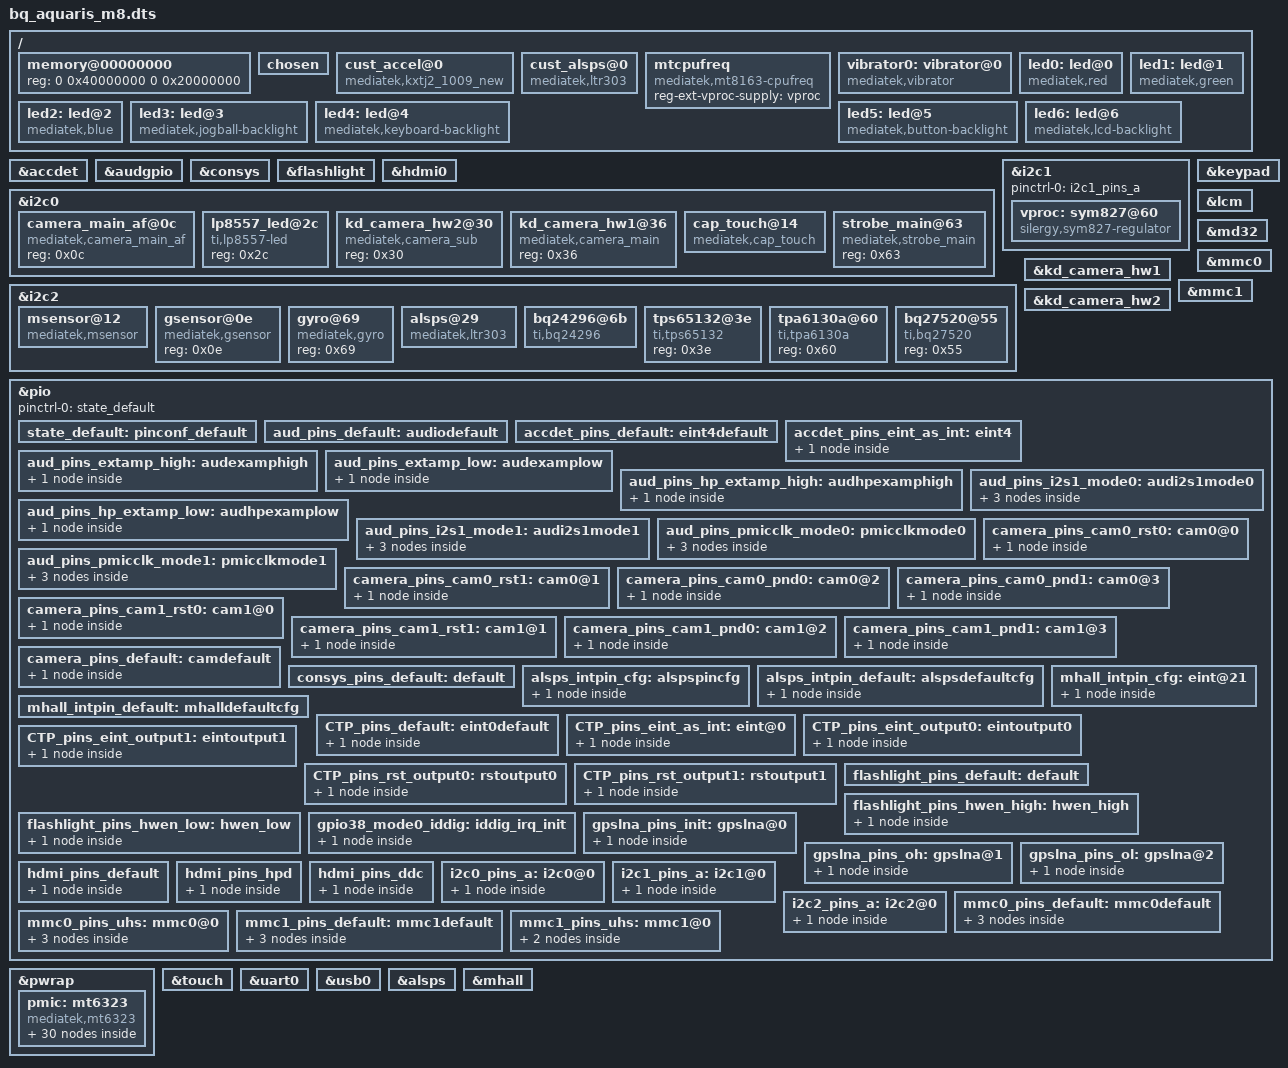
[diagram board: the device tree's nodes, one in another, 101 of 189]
/*
 * Copyright (c) 2014-2015 MediaTek Inc.
 *
 * This program is free software; you can redistribute it and/or modify
 * it under the terms of the GNU General Public License version 2 as
 * published by the Free Software Foundation.
 *
 * This program is distributed in the hope that it will be useful,
 * MERCHANTABILITY or FITNESS FOR A PARTICULAR PURPOSE.  See the
 * GNU General Public License for more details.
 */

/dts-v1/;

#include "mt8163.dtsi"
#include "bq_aquaris_m8_bat_setting.dtsi"

/ {
	memory@00000000 {
		device_type = "memory";
		reg = <0 0x40000000 0 0x20000000>;
	};

	/* chosen */
	chosen {
		bootargs = "console=ttyS0,921600n1 root=/dev/ram initrd=0x44000200,0x200000";
	};

/* sensor standardization */
	cust_accel@0 {
		compatible = "mediatek,kxtj2_1009_new";
		i2c_num	= <2>;
		i2c_addr = <0x0E 0 0 0>;
		direction = <7>;
		power_id = <0xffff>;
		power_vol = <0>;
		firlen = <0>;
		is_batch_supported = <0>;
	};

	cust_alsps@0 {
		compatible = "mediatek,ltr303";
		i2c_num = <2>;
		i2c_addr = <0x29>;
	};
/* sensor gpio standization */

	mtcpufreq {
		compatible = "mediatek,mt8163-cpufreq";
		reg-ext-vproc-supply = <&vproc>;
	};

	vibrator0:vibrator@0 {
		compatible = "mediatek,vibrator";
		vib_timer = <60>;
		vib_limit = <9>;
		vib_vol= <6>;
	};

/* led part */
	led0:led@0 {
		compatible = "mediatek,red";
		led_mode = <3>;
		data = <7>;
		pwm_config = <0 0 0 0 0>;
	};

	led1:led@1 {
		compatible = "mediatek,green";
		led_mode = <3>;
		data = <6>;
		pwm_config = <0 0 0 0 0>;
	};

	led2:led@2 {
		compatible = "mediatek,blue";
		led_mode = <3>;
		data = <8>;
		pwm_config = <0 0 0 0 0>;
	};

	led3:led@3 {
		compatible = "mediatek,jogball-backlight";
		led_mode = <0>;
		data = < >;
		pwm_config = <0 0 0 0 0>;
	};

	led4:led@4 {
		compatible = "mediatek,keyboard-backlight";
		led_mode = <0>;
		data = < >;
		pwm_config = <0 0 0 0 0>;
	};

	led5:led@5 {
		compatible = "mediatek,button-backlight";
		led_mode = <0>;
		data = < >;
		pwm_config = <0 0 0 0 0>;
	};

	led6:led@6 {
		compatible = "mediatek,lcd-backlight";
		led_mode = <5>;
		data = < >;
		pwm_config = <0 0 0 0 0>;
		gpios = <&pio 43 0>;
	};
/* led end*/
};

&accdet {
	interrupt-parent = <&pio>;
	interrupts = <4 IRQ_TYPE_LEVEL_LOW>;
	eint-debounce = <256>;
	accdet-gpio = <&pio 26 0>;
	accdet-mic-vol = <7>;
	headset-mode-setting = <0x900 0x400 1 0x3f0 0x800 0x800 0x20>;
	accdet-plugout-debounce = <20>;
	/*1:ACC mode, 2:low cost without in bias, 6:low cost with in bias*/
	accdet-mic-mode = <1>;
	/*0--MD_MAX--UP_MAX--DW_MAX*/
	headset-three-key-threshold = <0 80 220 500>;
	/*0--MD_MAX--VOICE_MAX--UP_MAX--DW_MAX*/
	headset-four-key-threshold = <0 58 121 192 450>;
	pinctrl-names = "default", "state_eint_as_int";
	pinctrl-0 = <&accdet_pins_default>;
	pinctrl-1 = <&accdet_pins_eint_as_int>;
	status = "okay";
};

&audgpio {
	pinctrl-names = "default",
			"audpmicclk-mode0",
			"audpmicclk-mode1",
			"audi2s1-mode0",
			"audi2s1-mode1",
			"extamp-pullhigh",
			"extamp-pulllow",
			"hp-extamp-pullhigh",
			"hp-extamp-pulllow";
	pinctrl-0 = <&aud_pins_default>;
	pinctrl-1 = <&aud_pins_pmicclk_mode0>;
	pinctrl-2 = <&aud_pins_pmicclk_mode1>;
	pinctrl-3 = <&aud_pins_i2s1_mode0>;
	pinctrl-4 = <&aud_pins_i2s1_mode1>;
	pinctrl-5 = <&aud_pins_extamp_high>;
	pinctrl-6 = <&aud_pins_extamp_low>;
	pinctrl-7 = <&aud_pins_hp_extamp_high>;
	pinctrl-8 = <&aud_pins_hp_extamp_low>;
	status = "okay";
};

&consys {
	pinctrl-names = "default", "gps_lna_state_init", "gps_lna_state_oh", "gps_lna_state_ol";
	pinctrl-0 = <&consys_pins_default>;
	pinctrl-1 = <&gpslna_pins_init>;
	pinctrl-2 = <&gpslna_pins_oh>;
	pinctrl-3 = <&gpslna_pins_ol>;
	vcn18-supply = <&mt6323_vcn18_reg>;
	vcn28-supply = <&mt6323_vcn28_reg>;
	vcn33_bt-supply = <&mt6323_vcn33_bt_reg>;
	vcn33_wifi-supply = <&mt6323_vcn33_wifi_reg>;
	status = "okay";
};

&flashlight {
	pinctrl-names = "default", "hwen_high", "hwen_low";
	pinctrl-0 = <&flashlight_pins_default>;
	pinctrl-1 = <&flashlight_pins_hwen_high>;
	pinctrl-2 = <&flashlight_pins_hwen_low>;
	status = "okay";
};

&hdmi0 {
	pinctrl-names = "default", "hdmi_hpd", "hdmi_ddc";
	pinctrl-0 = <&hdmi_pins_default>;
	pinctrl-1 = <&hdmi_pins_hpd>;
	pinctrl-2 = <&hdmi_pins_ddc>;
	hdmi_power_control = <&pio 27 0>;
};

&i2c0 {
	pinctrl-names = "default";
	pinctrl-0 = <&i2c0_pins_a>;
	md32,semaphore = <MD32_SEMAPHORE_I2C0>;
	status = "okay";

	camera_main_af@0c {
		compatible = "mediatek,camera_main_af";
		reg = <0x0c>;
	};

	lp8557_led@2c {
		compatible = "ti,lp8557-led";
		reg = <0x2c>;
	};

	kd_camera_hw2@30 { /* Fix me to right reg val */
		compatible = "mediatek,camera_sub";
		reg = <0x30>;
	};

	kd_camera_hw1@36 { /* Fix me to right reg val */
		compatible = "mediatek,camera_main";
		reg = <0x36>;
	};

	cap_touch@14 {
		compatible = "mediatek,cap_touch";
		reg = <0x14>;
		interrupt-parent = <&pio>;
		interrupts = <46 IRQ_TYPE_EDGE_FALLING>;
		int-gpio = <&pio 35 0>;
		rst-gpio = <&pio 45 0>;
	};

	strobe_main@63 {
		compatible = "mediatek,strobe_main";
		reg = <0x63>;
	};
};

&i2c1 {
	pinctrl-names = "default";
	pinctrl-0 = <&i2c1_pins_a>;
	status = "okay";

	vproc: sym827@60 {
		compatible = "silergy,sym827-regulator";
		reg = <0x60>;
		regulator-name = "vproc";
		regulator-min-microvolt = <600000>;
		regulator-max-microvolt = <1387500>;
		regulator-enable-ramp-delay = <400>;
		regulator-ramp-delay = <8333>;
		regulator-always-on;
		vsel-gpio = <&pio 34 0>;
	};
};

&i2c2 {
	pinctrl-names = "default";
	pinctrl-0 = <&i2c2_pins_a>;
	md32,semaphore = <MD32_SEMAPHORE_I2C2>;
	status = "okay";

	msensor@12{
		compatible = "mediatek,msensor";
		reg = <0x12>;
		rst-gpio = <&pio 52 0>;
	};

	gsensor@0e {
		compatible = "mediatek,gsensor";
		reg = <0x0e>;
	};

	gyro@69 {
		compatible = "mediatek,gyro";
		reg = <0x69>;
	};

	alsps@29 {
		compatible = "mediatek,ltr303";
		reg = <0x29>;
		als_level = <1 10 20 40 50 60 70 80 90 100 110 120 130 140 150 160 170 180 190 200 210 220 230 240 260 280 300 320 340 360 380 400 420 440 460 480 500 550 600 650 700 750 800 850 900 950 1000 1050 1100 1150 1200 1250 1300 1350 1400 1450 1500 2000 4000 4500 5000 6000>;
		als_value = <0 10 20 45 77 85 95 128 140 148 157 166 176 190 222 230 239 249 259 270 277 307 317 325 347 364 403 423 443 460 518 538 558 596 614 635 654 700 750 838 938 978 1036 1130 1163 1211 1310 1400 1555 1707 1860 1904 2054 2104 2351 2850 3100 3400 5800 7900 9600 10240>;		
		polling_mode_ps = <0>;
		polling_mode_als = <1>;
		power_id = <0xffff>;
		power_vol = <0>;
		ps_threshold_high               =  <30>;
		ps_threshold_low                =  <20>;
		is_batch_supported_ps   = <0>;
		is_batch_supported_als  = <0>;
		interrupt-parent = <&pio>;
   	interrupts = <8 IRQ_TYPE_EDGE_FALLING>;
		debounce = <8 0>;
	};

	bq24296@6b {
		compatible = "ti,bq24296";
		reg = <0x6b>;
		chg-ce-gpio = <&pio 22 0>;
	};
	tps65132@3e {
		compatible = "ti,tps65132";
		reg = <0x3e>;
	};
	tpa6130a@60 {
		compatible = "ti,tpa6130a";
		reg = <0x60>;
	};
	
	bq27520@55 {
		compatible = "ti,bq27520";
		reg = <0x55>;
	};
};

/* Main Cam */
&kd_camera_hw1 {
	reg-vcama-supply = <&mt6323_vcama_reg>;		/* AVDD */
	reg-vcamd-supply = <&mt6323_vcamd_reg>;		/* DVDD */
	reg-vcamio-supply = <&mt6323_vcamio_reg>;	/* DOVDD */
	reg-vcamaf-supply = <&mt6323_vcamaf_reg>;	/* AFVDD */

	pinctrl-names = "default", "cam0_rst0", "cam0_rst1", "cam0_pnd0", "cam0_pnd1",
			"cam1_rst0", "cam1_rst1", "cam1_pnd0", "cam1_pnd1","cam_ldo0_0", "cam_ldo0_1";
	pinctrl-0 = <&camera_pins_default>;
	pinctrl-1 = <&camera_pins_cam0_rst0>;
	pinctrl-2 = <&camera_pins_cam0_rst1>;
	pinctrl-3 = <&camera_pins_cam0_pnd0>;
	pinctrl-4 = <&camera_pins_cam0_pnd1>;
	pinctrl-5 = <&camera_pins_cam1_rst0>;
	pinctrl-6 = <&camera_pins_cam1_rst1>;
	pinctrl-7 = <&camera_pins_cam1_pnd0>;
	pinctrl-8 = <&camera_pins_cam1_pnd1>;
/*
	pinctrl-9 = <&camera_pins_cam_ldo0_0>;
	pinctrl-10 = <&camera_pins_cam_ldo0_1>;
*/
	status = "okay";
};

/* Sub Cam */
/* FIX ME: same power pins as Main ? */
&kd_camera_hw2{
	reg-vcama-supply = <&mt6323_vcama_reg>;		/* AVDD */
	reg-vcamd-supply = <&mt6323_vcamd_reg>;		/* DVDD */
	reg-vcamio-supply = <&mt6323_vcamio_reg>;	/* DOVDD */
	reg-vcamaf-supply = <&mt6323_vcamaf_reg>;	/* AFVDD */
};

&keypad {
	mediatek,kpd-key-debounce = <1024>;
	mediatek,kpd-sw-pwrkey = <116>;
	mediatek,kpd-hw-pwrkey = <8>;
	mediatek,kpd-sw-rstkey  = <114>;
	mediatek,kpd-hw-rstkey = <17>;
	mediatek,kpd-use-extend-type = <0>;
	/*HW Keycode [0~71] -> Linux Keycode*/
	mediatek,kpd-hw-map-num = <72>;
	mediatek,kpd-hw-init-map = <115 0 0 0 0 0 0 0 0 0 0 0 0 0 0 0 0 0 0 0 0 0 0 0
			0 0 0 0 0 0 0 0 0 0 0 0 0 0 0 0 0 0 0 0 0 0 0 0
			0 0 0 0 0 0 0 0 0 0 0 0 0 0 0 0 0 0 0 0 0 0 0 0 >;
	mediatek,kpd-pwrkey-eint-gpio = <0>;
	mediatek,kpd-pwkey-gpio-din  = <0>;
	mediatek,kpd-hw-dl-key0 = <0>;
	mediatek,kpd-hw-dl-key1 = <17>;
	mediatek,kpd-hw-dl-key2 = <8>;
	mediatek,kpd-hw-recovery-key = <17>;
	mediatek,kpd-hw-factory-key  = <0>;
};

&lcm {
	lcm_power_gpio = <&pio 84 0>;
	lcm_reset_gpio = <&pio 83 0>;
	reg-lcm-supply = <&mt6323_vgp3_reg>;
};

&md32 {
	status = "okay";
};

&mmc0 {
	pinctrl-names = "default", "state_uhs";
	pinctrl-0 = <&mmc0_pins_default>;
	pinctrl-1 = <&mmc0_pins_uhs>;
	status = "okay";
	bus-width = <8>;
	latch-ck = <1>;
	max-frequency = <200000000>;
	cap-mmc-highspeed;
	mmc-hs200-1_8v;
	cap-mmc-hw-reset;
	vmmc-supply = <&mt6323_vemc3v3_reg>;
	vqmmc-supply = <&mt6323_vio18_reg>;
	non-removable;
};

&mmc1 {
	pinctrl-names = "default", "state_uhs";
	pinctrl-0 = <&mmc1_pins_default>;
	pinctrl-1 = <&mmc1_pins_uhs>;
	status = "okay";
	bus-width = <4>;
	latch-ck = <1>;
	max-frequency = <200000000>;
	cap-sd-highspeed;
	sd-uhs-sdr50;
	sd-uhs-sdr104;
	cd-gpios = <&pio 28 0>;
	vmmc-supply = <&mt6323_vmch_reg>;
	vqmmc-supply = <&mt6323_vmc_reg>;
};

&pio {
	pinctrl-names = "default";
	pinctrl-0 = <&state_default>;

	state_default:pinconf_default {
	};

	aud_pins_default: audiodefault {
	};

	accdet_pins_default: eint4default {
	};

	accdet_pins_eint_as_int: eint4 {
		pins_cmd_dat {
			pins = <MT8163_PIN_26_EINT4__FUNC_GPIO26>;
			bias-disable;
		};
	};

	aud_pins_extamp_high: audexamphigh {
		pins_cmd_dat {
			pins = <MT8163_PIN_44_EINT12__FUNC_GPIO44>;
			slew-rate = <1>;
			output-high;
		};
	};

	aud_pins_extamp_low: audexamplow {
		pins_cmd_dat {
			pins = <MT8163_PIN_44_EINT12__FUNC_GPIO44>;
			slew-rate = <1>;
			output-low;
		};
	};

	aud_pins_hp_extamp_high: audhpexamphigh {
		pins_cmd_dat {
			pins = <MT8163_PIN_43_EINT11__FUNC_GPIO43>;
			slew-rate = <1>;
			output-high;
		};
	};

	aud_pins_hp_extamp_low: audhpexamplow {
		pins_cmd_dat {
			pins = <MT8163_PIN_43_EINT11__FUNC_GPIO43>;
			slew-rate = <1>;
			output-low;
		};
	};

	aud_pins_i2s1_mode0: audi2s1mode0 {
		pins_cmd0_dat {
			pins = <MT8163_PIN_46_EINT14__FUNC_GPIO46>;
		};
		pins_cmd1_dat {
			pins = <MT8163_PIN_47_EINT15__FUNC_GPIO47>;
		};
		pins_cmd2_dat {
			pins = <MT8163_PIN_48_EINT16__FUNC_GPIO48>;
		};
	};

	aud_pins_i2s1_mode1: audi2s1mode1 {
		pins_cmd0_dat {
			pins = <MT8163_PIN_46_EINT14__FUNC_I2S1_DO>;
		};
		pins_cmd1_dat {
			pins = <MT8163_PIN_47_EINT15__FUNC_I2S1_LRCK>;
		};
		pins_cmd2_dat {
			pins = <MT8163_PIN_48_EINT16__FUNC_I2S1_BCK>;
		};
	};

	aud_pins_pmicclk_mode0: pmicclkmode0 {
		pins_cmd0_dat {
			pins = <MT8163_PIN_7_AUD_CLK_MOSI__FUNC_GPIO7>;
		};
		pins_cmd1_dat {
			pins = <MT8163_PIN_8_AUD_DAT_MISO__FUNC_GPIO8>;
		};
		pins_cmd2_dat {
			pins = <MT8163_PIN_9_AUD_DAT_MOSI__FUNC_AUD_DAT_MOSI>;
		};
	};

	aud_pins_pmicclk_mode1: pmicclkmode1 {
		pins_cmd0_dat {
			pins = <MT8163_PIN_7_AUD_CLK_MOSI__FUNC_AUD_CLK_MOSI>;
		};
		pins_cmd1_dat {
			pins = <MT8163_PIN_8_AUD_DAT_MISO__FUNC_AUD_DAT_MISO>;
		};
		pins_cmd2_dat {
			pins = <MT8163_PIN_9_AUD_DAT_MOSI__FUNC_AUD_DAT_MOSI>;
		};
	};

	/* CAMERA GPIO standardization */
	/* Project Dependency : tb8163m1 */
	camera_pins_cam0_rst0: cam0@0 {
		pins_cmd_dat {
			pins = <MT8163_PIN_53_SPI_CS__FUNC_GPIO53>;/*GPIO_CAMERA_CMRST_PIN*/
			slew-rate = <1>; /*direction 0:in, 1:out*/
			output-low;/*direction out used only. output_low or high*/
		};
	};
	camera_pins_cam0_rst1: cam0@1 {
		pins_cmd_dat {
			pins = <MT8163_PIN_53_SPI_CS__FUNC_GPIO53>;/*GPIO_CAMERA_CMRST_PIN*/
			slew-rate = <1>;
			output-high;
		};
	};
	camera_pins_cam0_pnd0: cam0@2 {
		pins_cmd_dat {
			pins = <MT8163_PIN_56_SPI_MO__FUNC_GPIO56>;/*GPIO_CAMERA_CMPDN_PIN*/
			slew-rate = <1>;
			output-low;
		};
	};
	camera_pins_cam0_pnd1: cam0@3 {
		pins_cmd_dat {
			pins = <MT8163_PIN_56_SPI_MO__FUNC_GPIO56>;/*GPIO_CAMERA_CMPDN_PIN*/
			slew-rate = <1>;
			output-high;
		};
	};
	camera_pins_cam1_rst0: cam1@0 {
		pins_cmd_dat {
			pins = <MT8163_PIN_55_SPI_MI__FUNC_GPIO55>;/*GPIO_CAMERA_CMRST1_PIN*/
			slew-rate = <1>; /*direction 0:in, 1:out*/
			output-low;/*direction out used only. output_low or high*/
		};
	};
	camera_pins_cam1_rst1: cam1@1 {
		pins_cmd_dat {
			pins = <MT8163_PIN_55_SPI_MI__FUNC_GPIO55>;/*GPIO_CAMERA_CMRST1_PIN*/
			slew-rate = <1>;
			output-high;
		};
	};
	camera_pins_cam1_pnd0: cam1@2 {
		pins_cmd_dat {
			pins = <MT8163_PIN_54_SPI_CK__FUNC_GPIO54>;/*GPIO_CAMERA_CMPDN1_PIN*/
			slew-rate = <1>;
			output-low;
		};
	};
	camera_pins_cam1_pnd1: cam1@3 {
		pins_cmd_dat {
			pins = <MT8163_PIN_54_SPI_CK__FUNC_GPIO54>;/*GPIO_CAMERA_CMPDN1_PIN*/
			slew-rate = <1>;
			output-high;
		};
	};

/*
	camera_pins_cam_ldo0_0: cam@0 {
		pins_cmd_dat {
			pins = <PINMUX_GPIO68__FUNC_GPIO68>;
			slew-rate = <1>;
			output-low;
		};
	};
	camera_pins_cam_ldo0_1: cam@1 {
		pins_cmd_dat {
			pins = <PINMUX_GPIO68__FUNC_GPIO68>;
			slew-rate = <1>;
			output-high;
		};
	};
*/

	/* Set MCLK Pin default mode */
	camera_pins_default: camdefault {
		pins_cmd_dat {
			pins = <MT8163_PIN_119_CMMCLK__FUNC_CMMCLK>;	/*MCLK*/
		};
	};

	/* CONSYS GPIO Settings - Start */
	consys_pins_default: default {

	};
	/* CONSYS GPIO Settings - End */

	alsps_intpin_cfg: alspspincfg {

	    pins_cmd_dat {
			pins = <MT8163_PIN_30_EINT8__FUNC_GPIO30>;
			slew-rate = <0>;
			bias-pull-up = <00>;
		};
	};

	alsps_intpin_default: alspsdefaultcfg {
	    pins_cmd_dat {
			pins = <MT8163_PIN_30_EINT8__FUNC_GPIO30>;
			slew-rate = <0>;
			bias-pull-up = <00>;
		};
	};

	mhall_intpin_default: mhalldefaultcfg {

	};

	mhall_intpin_cfg: eint@21 {
	    pins_cmd_dat {
			pins = <MT8163_PIN_142_EINT21__FUNC_GPIO142>;
			slew-rate = <0>;
			bias-disable;
		};
	};

	CTP_pins_default: eint0default {
		pins_cmd_dat {
			pins = <MT8163_PIN_35_KPROW2__FUNC_GPIO35>;
			slew-rate = <0>;
			bias-disable;
		};
	};

	CTP_pins_eint_as_int: eint@0 {
		pins_cmd_dat {
			pins = <MT8163_PIN_35_KPROW2__FUNC_GPIO35>;
			slew-rate = <0>;
			bias-pull-up = <00>;
		};
	};

	CTP_pins_eint_output0: eintoutput0 {
		pins_cmd_dat {
			pins = <MT8163_PIN_35_KPROW2__FUNC_GPIO35>;
			slew-rate = <1>;
			output-low;
		};
	};

	CTP_pins_eint_output1: eintoutput1 {
		pins_cmd_dat {
			pins = <MT8163_PIN_35_KPROW2__FUNC_GPIO35>;
			slew-rate = <1>;
			output-high;
		};
	};

	CTP_pins_rst_output0: rstoutput0 {
		pins_cmd_dat {
			pins = <MT8163_PIN_45_EINT13__FUNC_GPIO45>;
			slew-rate = <1>;
			output-low;
		};
	};

	CTP_pins_rst_output1: rstoutput1 {
		pins_cmd_dat {
			pins = <MT8163_PIN_45_EINT13__FUNC_GPIO45>;
			slew-rate = <1>;
			output-high;
		};
	};

	flashlight_pins_default: default {
	};

	flashlight_pins_hwen_high: hwen_high {
		pins_cmd_dat {
			pins = <MT8163_PIN_117_CMDAT0__FUNC_GPIO117>;
			slew-rate = <1>;
			output-high;
		};
	};

	flashlight_pins_hwen_low: hwen_low {
		pins_cmd_dat {
			pins = <MT8163_PIN_117_CMDAT0__FUNC_GPIO117>;
			slew-rate = <1>;
			output-low;
		};
	};

/* USB GPIO start */
	gpio38_mode0_iddig: iddig_irq_init {
		pins_cmd_dat {
			pins = <MT8163_PIN_38_KPCOL2__FUNC_GPIO38>;
			slew-rate = <0>;
			bias-pull-up = <00>;
		};
	};
/* USB GPIO end */

	/* CONSYS GPIO Settings - Start */
	gpslna_pins_init: gpslna@0 {
		pins_cmd_dat {
			pinmux = <MT8163_PIN_118_CMDAT1__FUNC_GPIO118>;
			slew-rate = <0>;
			bias-disable;
			output-low;
		};
	};

	gpslna_pins_oh: gpslna@1 {
		pins_cmd_dat {
			pinmux = <MT8163_PIN_118_CMDAT1__FUNC_GPIO118>;
			slew-rate = <1>;
			output-high;
		};
	};

	gpslna_pins_ol: gpslna@2 {
		pins_cmd_dat {
			pinmux = <MT8163_PIN_118_CMDAT1__FUNC_GPIO118>;
			slew-rate = <1>;
			output-low;
		};
	};
	/* CONSYS GPIO Settings - End */

	hdmi_pins_default: hdmi_pins_default {
		pins_cmd_dat {
			pinmux = <MT8163_PIN_27_EINT5__FUNC_GPIO27>;
			slew-rate = <1>;
			bias-pull-up;
			output-high;
		};
	};

	hdmi_pins_hpd: hdmi_pins_hpd {
		pins_cmd_dat {
			pinmux = <MT8163_PIN_139_HTPLG__FUNC_HTPLG>;
			slew-rate = <0>;
			bias-pull-down;
		};
	};

	hdmi_pins_ddc: hdmi_pins_ddc {
		pins_cmd_dat {
			pinmux = <MT8163_PIN_140_HDMISCK__FUNC_HDMISCK>,
				<MT8163_PIN_141_HDMISD__FUNC_HDMISD>;
		};
	};


	i2c0_pins_a: i2c0@0 {
		pins1 {
			pinmux = <MT8163_PIN_75_SDA0__FUNC_SDA0_0>,
				 <MT8163_PIN_76_SCL0__FUNC_SCL0_0>;
			bias-disable;
		};
	};

	i2c1_pins_a: i2c1@0 {
		pins1 {
			pinmux = <MT8163_PIN_57_SDA1__FUNC_SDA1_0>,
				 <MT8163_PIN_58_SCL1__FUNC_SCL1_0>;
			bias-disable;
		};
	};

	i2c2_pins_a: i2c2@0 {
		pins1 {
			pinmux = <MT8163_PIN_77_SDA2__FUNC_SDA2_0>,
				 <MT8163_PIN_78_SCL2__FUNC_SCL2_0>;
			bias-disable;
		};
	};

	mmc0_pins_default: mmc0default {
		pins_cmd_dat {
			pinmux = <MT8163_PIN_137_MSDC0_DAT0__FUNC_MSDC0_DAT0>,
				<MT8163_PIN_136_MSDC0_DAT1__FUNC_MSDC0_DAT1>,
				<MT8163_PIN_135_MSDC0_DAT2__FUNC_MSDC0_DAT2>,
				<MT8163_PIN_134_MSDC0_DAT3__FUNC_MSDC0_DAT3>,
				<MT8163_PIN_130_MSDC0_DAT4__FUNC_MSDC0_DAT4>,
				<MT8163_PIN_129_MSDC0_DAT5__FUNC_MSDC0_DAT5>,
				<MT8163_PIN_128_MSDC0_DAT6__FUNC_MSDC0_DAT6>,
				<MT8163_PIN_127_MSDC0_DAT7__FUNC_MSDC0_DAT7>,
				<MT8163_PIN_132_MSDC0_CMD__FUNC_MSDC0_CMD>;
			input-enable;
			bias-pull-up;
		};

		pins_clk {
			pinmux = <MT8163_PIN_133_MSDC0_CLK__FUNC_MSDC0_CLK>;
			bias-pull-down;
		};

		pins_rst {
			pinmux = <MT8163_PIN_131_MSDC0_RSTB__FUNC_MSDC0_RSTB>;
			bias-pull-up;
		};
	};

	mmc0_pins_uhs: mmc0@0{
		pins_cmd_dat {
			pinmux = <MT8163_PIN_137_MSDC0_DAT0__FUNC_MSDC0_DAT0>,
				<MT8163_PIN_136_MSDC0_DAT1__FUNC_MSDC0_DAT1>,
				<MT8163_PIN_135_MSDC0_DAT2__FUNC_MSDC0_DAT2>,
				<MT8163_PIN_134_MSDC0_DAT3__FUNC_MSDC0_DAT3>,
				<MT8163_PIN_130_MSDC0_DAT4__FUNC_MSDC0_DAT4>,
				<MT8163_PIN_129_MSDC0_DAT5__FUNC_MSDC0_DAT5>,
				<MT8163_PIN_128_MSDC0_DAT6__FUNC_MSDC0_DAT6>,
				<MT8163_PIN_127_MSDC0_DAT7__FUNC_MSDC0_DAT7>,
				<MT8163_PIN_132_MSDC0_CMD__FUNC_MSDC0_CMD>;
			input-enable;
			drive-strength = <MTK_DRIVE_6mA>;
			bias-pull-up = <MTK_PUPD_SET_R1R0_01>;
		};

		pins_clk {
			pinmux = <MT8163_PIN_133_MSDC0_CLK__FUNC_MSDC0_CLK>;
			drive-strength = <MTK_DRIVE_6mA>;
			bias-pull-down = <MTK_PUPD_SET_R1R0_01>;
		};

		pins_rst {
			pinmux = <MT8163_PIN_131_MSDC0_RSTB__FUNC_MSDC0_RSTB>;
			bias-pull-up;
		};
	};

	mmc1_pins_default: mmc1default {
		pins_cmd_dat {
			pinmux = <MT8163_PIN_123_MSDC1_DAT0__FUNC_MSDC1_DAT0>,
				<MT8163_PIN_124_MSDC1_DAT1__FUNC_MSDC1_DAT1>,
				<MT8163_PIN_125_MSDC1_DAT2__FUNC_MSDC1_DAT2>,
				<MT8163_PIN_126_MSDC1_DAT3__FUNC_MSDC1_DAT3>,
				<MT8163_PIN_121_MSDC1_CMD__FUNC_MSDC1_CMD>;
			input-enable;
			drive-strength = <MTK_DRIVE_32mA>;
			bias-pull-up = <MTK_PUPD_SET_R1R0_10>;
		};

		pins_clk {
			pinmux = <MT8163_PIN_122_MSDC1_CLK__FUNC_MSDC1_CLK>;
			bias-pull-down;
			drive-strength = <MTK_DRIVE_32mA>;
		};

		pins_insert {
			pinmux = <MT8163_PIN_28_EINT6__FUNC_GPIO28>;
			bias-pull-up;
		};
	};

	mmc1_pins_uhs: mmc1@0 {
		pins_cmd_dat {
			pinmux = <MT8163_PIN_123_MSDC1_DAT0__FUNC_MSDC1_DAT0>,
				<MT8163_PIN_124_MSDC1_DAT1__FUNC_MSDC1_DAT1>,
				<MT8163_PIN_125_MSDC1_DAT2__FUNC_MSDC1_DAT2>,
				<MT8163_PIN_126_MSDC1_DAT3__FUNC_MSDC1_DAT3>,
				<MT8163_PIN_121_MSDC1_CMD__FUNC_MSDC1_CMD>;
			input-enable;
			drive-strength = <MTK_DRIVE_32mA>;
			bias-pull-up = <MTK_PUPD_SET_R1R0_10>;
		};

		pins_clk {
			pinmux = <MT8163_PIN_122_MSDC1_CLK__FUNC_MSDC1_CLK>;
			drive-strength = <MTK_DRIVE_32mA>;
			bias-pull-down = <MTK_PUPD_SET_R1R0_10>;
		};
	};
};

&pwrap {
	pmic: mt6323 {
		compatible = "mediatek,mt6323";

		pmicmt6323: pmicmt6323 {
			compatible = "mediatek,mt6323-pmic";
			interrupt-parent = <&pio>;
			interrupts = <24 IRQ_TYPE_LEVEL_HIGH>;
		};

		regulators {

			compatible = "mediatek,mt6323-regulator";

			mt6323_vproc_reg: buck_vproc {
				regulator-name = "vproc";
				regulator-min-microvolt = < 700000>;
				regulator-max-microvolt = <1350000>;
				regulator-ramp-delay = <12500>;
				regulator-always-on;
				regulator-boot-on;
			};

			mt6323_vsys_reg: buck_vsys {
				regulator-name = "vsys";
				regulator-min-microvolt = <1400000>;
				regulator-max-microvolt = <2987500>;
				regulator-ramp-delay = <25000>;
				regulator-always-on;
				regulator-boot-on;
			};

			mt6323_vpa_reg: buck_vpa {
				regulator-name = "vpa";
				regulator-min-microvolt = < 500000>;
				regulator-max-microvolt = <3650000>;
			};

			mt6323_vtcxo_reg: ldo_vtcxo {
				regulator-name = "vtcxo";
				regulator-min-microvolt = <2800000>;
				regulator-max-microvolt = <2800000>;
				regulator-enable-ramp-delay = <90>;
				regulator-always-on;
				regulator-boot-on;
			};

			mt6323_vcn28_reg: ldo_vcn28 {
				regulator-name = "vcn28";
				regulator-min-microvolt = <2800000>;
				regulator-max-microvolt = <2800000>;
				regulator-enable-ramp-delay = <185>;
			};

			mt6323_vcn33_bt_reg: ldo_vcn33_bt {
				regulator-name = "vcn33_bt";
				regulator-min-microvolt = <3300000>;
				regulator-max-microvolt = <3600000>;
				regulator-enable-ramp-delay = <185>;
			};

			mt6323_vcn33_wifi_reg: ldo_vcn33_wifi {
				regulator-name = "vcn33_wifi";
				regulator-min-microvolt = <3300000>;
				regulator-max-microvolt = <3600000>;
				regulator-enable-ramp-delay = <185>;
			};

			mt6323_va_reg: ldo_va {
				regulator-name = "va";
				regulator-min-microvolt = <2800000>;
				regulator-max-microvolt = <2800000>;
				regulator-enable-ramp-delay = <216>;
				regulator-always-on;
				regulator-boot-on;
			};

			mt6323_vcama_reg: ldo_vcama {
				regulator-name = "vcama";
				regulator-min-microvolt = <1500000>;
				regulator-max-microvolt = <2800000>;
				regulator-enable-ramp-delay = <216>;
			};

			mt6323_vio28_reg: ldo_vio28 {
				regulator-name = "vio28";
				regulator-min-microvolt = <2800000>;
				regulator-max-microvolt = <2800000>;
				regulator-enable-ramp-delay = <216>;
				regulator-always-on;
				regulator-boot-on;
			};

			mt6323_vusb_reg: ldo_vusb {
				regulator-name = "vusb";
				regulator-min-microvolt = <3300000>;
				regulator-max-microvolt = <3300000>;
				regulator-enable-ramp-delay = <216>;
				regulator-boot-on;
			};

			mt6323_vmc_reg: ldo_vmc {
				regulator-name = "vmc";
				regulator-min-microvolt = <1800000>;
				regulator-max-microvolt = <3300000>;
				regulator-enable-ramp-delay = <36>;
				regulator-boot-on;
			};

			mt6323_vmch_reg: ldo_vmch {
				regulator-name = "vmch";
				regulator-min-microvolt = <3000000>;
				regulator-max-microvolt = <3300000>;
				regulator-enable-ramp-delay = <36>;
				regulator-boot-on;
			};

			mt6323_vemc3v3_reg: ldo_vemc3v3 {
				regulator-name = "vemc3v3";
				regulator-min-microvolt = <3000000>;
				regulator-max-microvolt = <3300000>;
				regulator-enable-ramp-delay = <36>;
				regulator-boot-on;
			};

			mt6323_vgp1_reg: ldo_vgp1 {
				regulator-name = "vgp1";
				regulator-min-microvolt = <1200000>;
				regulator-max-microvolt = <3300000>;
				regulator-enable-ramp-delay = <216>;
			};

			mt6323_vgp2_reg: ldo_vgp2 {
				regulator-name = "vgp2";
				regulator-min-microvolt = <1200000>;
				regulator-max-microvolt = <3000000>;
				regulator-enable-ramp-delay = <216>;
			};

			mt6323_vgp3_reg: ldo_vgp3 {
				regulator-name = "vgp3";
				regulator-min-microvolt = <1200000>;
				regulator-max-microvolt = <1800000>;
				regulator-enable-ramp-delay = <216>;
			};

			mt6323_vcn18_reg: ldo_vcn18 {
				regulator-name = "vcn18";
				regulator-min-microvolt = <1800000>;
				regulator-max-microvolt = <1800000>;
				regulator-enable-ramp-delay = <216>;
			};

			mt6323_vsim1_reg: ldo_vsim1 {
				regulator-name = "vsim1";
				regulator-min-microvolt = <1800000>;
				regulator-max-microvolt = <3000000>;
				regulator-enable-ramp-delay = <216>;
			};

			mt6323_vsim2_reg: ldo_vsim2 {
				regulator-name = "vsim2";
				regulator-min-microvolt = <1800000>;
				regulator-max-microvolt = <3000000>;
				regulator-enable-ramp-delay = <216>;
			};

			mt6323_vrtc_reg: ldo_vrtc {
				regulator-name = "vrtc";
				regulator-min-microvolt = <2800000>;
				regulator-max-microvolt = <2800000>;
				regulator-always-on;
				regulator-boot-on;
			};

			mt6323_vcamaf_reg: ldo_vcamaf {
				regulator-name = "vcamaf";
				regulator-min-microvolt = <1200000>;
				regulator-max-microvolt = <3300000>;
				regulator-enable-ramp-delay = <216>;
			};

			mt6323_vibr_reg: ldo_vibr {
				regulator-name = "vibr";
				regulator-min-microvolt = <1200000>;
				regulator-max-microvolt = <3300000>;
				regulator-enable-ramp-delay = <36>;
			};

			mt6323_vrf18_reg: ldo_vrf18 {
				regulator-name = "vrf18";
				regulator-min-microvolt = <1825000>;
				regulator-max-microvolt = <1825000>;
				regulator-enable-ramp-delay = <187>;
			};

			mt6323_vm_reg: ldo_vm {
				regulator-name = "vm";
				regulator-min-microvolt = <1200000>;
				regulator-max-microvolt = <1800000>;
				regulator-enable-ramp-delay = <216>;
				regulator-always-on;
				regulator-boot-on;
			};

			mt6323_vio18_reg: ldo_vio18 {
				regulator-name = "vio18";
				regulator-min-microvolt = <1800000>;
				regulator-max-microvolt = <1800000>;
				regulator-enable-ramp-delay = <216>;
				regulator-always-on;
				regulator-boot-on;
			};

			mt6323_vcamd_reg: ldo_vcamd {
				regulator-name = "vcamd";
				regulator-min-microvolt = <1200000>;
				regulator-max-microvolt = <1800000>;
				regulator-enable-ramp-delay = <216>;
			};

			mt6323_vcamio_reg: ldo_vcamio {
				regulator-name = "vcamio";
				regulator-min-microvolt = <1800000>;
				regulator-max-microvolt = <1800000>;
				regulator-enable-ramp-delay = <216>;
			};
		};
	};
};

&touch {
	vtouch-supply = <&mt6323_vgp2_reg>;
	tpd-resolution = <800 1280>;
	tpd-convert-ratio = <1 1>;
	use-tpd-button = <1>;
	tpd-key-num = <0>;
	tpd-key-local= <0 0 0 0>;
	tpd-key-dim-local = <0 0 0 0 0 0 0 0 0 0 0 0 0 0 0 0>;
	tpd-max-touch-num = <5>;
	tpd-filter-enable = <1>;
	tpd-filter-pixel-density = <124>;
	tpd-filter-custom-prameters = <0 0 0 0 0 0 0 0 0 0 0 0>;
	tpd-filter-custom-speed = <0 0 0>;
	pinctrl-names = "default", "state_eint_as_int", "state_eint_output0", "state_eint_output1",
		"state_rst_output0", "state_rst_output1";
	pinctrl-0 = <&CTP_pins_default>;
	pinctrl-1 = <&CTP_pins_eint_as_int>;
	pinctrl-2 = <&CTP_pins_eint_output0>;
	pinctrl-3 = <&CTP_pins_eint_output1>;
	pinctrl-4 = <&CTP_pins_rst_output0>;
	pinctrl-5 = <&CTP_pins_rst_output1>;
	status = "okay";
};

&uart0 {
	status="okay";
};

&usb0 {
	vusb-supply = <&mt6323_vusb_reg>;
	pinctrl-names = "iddig_irq_init";
	pinctrl-0 = <&gpio38_mode0_iddig>;
	iddig_gpio = <&pio 38 0>;
	status = "okay";
};

&alsps {
	pinctrl-names = "pin_default", "pin_cfg";
	pinctrl-0 = <&alsps_intpin_default>;
	pinctrl-1 = <&alsps_intpin_cfg>;
	status = "okay";
};

&mhall {
	interrupt-parent = <&pio>;
	interrupts = <21 IRQ_TYPE_LEVEL_LOW>;
	debounce = <21 4000>;
	pinctrl-names = "pin_default", "pin_cfg";
	pinctrl-0 = <&mhall_intpin_default>;
	pinctrl-1 = <&mhall_intpin_cfg>;
	status = "okay";
	int = <&pio 142 0>;
};
